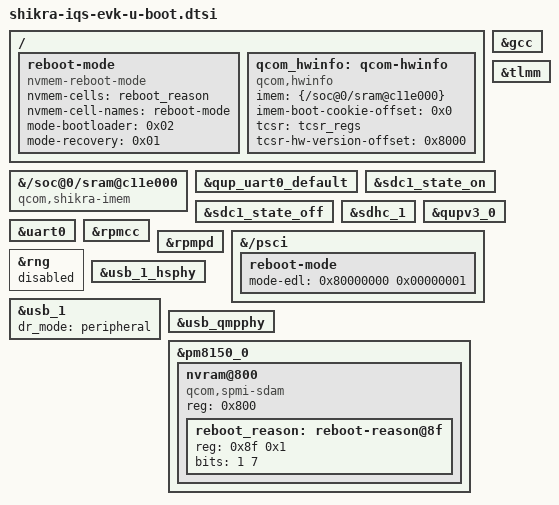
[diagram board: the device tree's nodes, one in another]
// SPDX-License-Identifier: BSD-3-Clause
/*
 * Copyright (c) Qualcomm Technologies, Inc. and/or its subsidiaries.
 */

/ {
	reboot-mode {
		compatible = "nvmem-reboot-mode";
		nvmem-cells = <&reboot_reason>;
		nvmem-cell-names = "reboot-mode";

		mode-bootloader = <0x02>;
		mode-recovery   = <0x01>;
	};

	qcom_hwinfo: qcom-hwinfo {
		compatible = "qcom,hwinfo";

		imem = <&{/soc@0/sram@c11e000}>;
		imem-boot-cookie-offset = <0x0>;

		tcsr = <&tcsr_regs>;
		tcsr-hw-version-offset = <0x8000>;
	};
};

&{/soc@0/sram@c11e000} {
	compatible = "qcom,shikra-imem", "syscon", "simple-mfd";
};

/* Keep the console and QUPFW storage paths in the SPL device tree. */
&gcc {
	bootph-all;
};

&tlmm {
	bootph-all;
};

&qup_uart0_default {
	bootph-all;
};

&sdc1_state_on {
	bootph-all;
};

&sdc1_state_off {
	bootph-all;
};

&sdhc_1 {
	bootph-all;
};

&qupv3_0 {
	bootph-all;
};

&uart0 {
	bootph-all;
};

/* Retain the RPM clock and power-domain providers for boot consumers. */
&rpmcc {
	bootph-all;
};

&rpmpd {
	bootph-all;
};

/* Enter Qualcomm EDL/download mode via "reset -edl". */
&{/psci} {
	reboot-mode {
		mode-edl = <0x80000000 0x00000001>;
	};
};

&rng {
	status = "disabled";
};

&usb_1_hsphy {
	status = "okay";
};

&usb_1 {
	dr_mode = "peripheral";

	status = "okay";
};

&usb_qmpphy {
	status = "okay";
};

&pm8150_0 {
	/* Virtual NVMEM node for PON-based reboot reason storage */
	nvram@800 {
		compatible = "qcom,spmi-sdam";
		reg = <0x800>;
		#address-cells = <1>;
		#size-cells = <1>;
		ranges = <0x00 0x800 0x100>;

		/* Reboot reason cell at PON_SOFT_RB_SPARE (0x88F) */
		reboot_reason: reboot-reason@8f {
			reg = <0x8f 0x1>;
			bits = <1 7>;
		};
	};
};
